# ESP32C3 register map
File version: 1.0
CPU: RISC-V RV32IMC single-core 1, little endian, no MPU, FPU, 3 interrupt priority bits
Registers are 32-bit, read-write, reset 0x0 unless marked. A register's access mark holds for its fields unless they carry their own. Offsets are from the block's base; lines under a group give offsets from that group; [hi:lo] are bit positions; {n}, {i} and the like mark numbered series; 'fields as' and 'values as' point back to an identical list; <NAME> marks a mode.

## Memory map
0x00000000 GPIO_SD size 0xE0
0x00000000 I2C size 0x440
0x00000000 I2S size 0x2E0
0x00000000 INTERRUPT_CORE0 size 0xCE0
0x00000000 MCPWM
0x00000000 SPI size 0x4A0
0x00000000 SPI_MEM size 0x5E0
0x00000000 TIMG size 0x340
0x00000000 UHCI size 0x420
0x60000000 UART size 0x420
0x60002000 SPI1
0x60003000 SPI0
0x60004000 GPIO size 0x18E0
0x60005000 FE2
0x60006000 FE
0x60008000 RTCCNTL size 0x960
0x60008800 EFUSE size 0xE60
0x60009000 IO_MUX
0x6000E000 RTC_I2C size 0x3E0
0x60010000 UART1
0x60013000 I2C_EXT
0x60014000 UHCI0
0x60016000 RMT size 0x340
0x60019000 LEDC size 0x580
0x6001CC00 NRX
0x6001D000 BB
0x6001F000 TIMERGROUP0
0x60020000 TIMERGROUP1
0x60023000 SYS_TIMER size 0x3C0
0x60024000 SPI2
0x60026000 APB_CTRL size 0x500
0x60026000 SYSCON size 0x500
0x6002B000 TWAI
0x6002D000 I2S0
0x6003A000 AES
0x6003B000 SHA
0x6003C000 RSA
0x6003D000 DIGITAL_SIGNATURE
0x6003E000 HMAC
0x6003F000 GDMA size 0xBA0
0x60040000 APB_SARADC size 0x340
0x600C0000 SYSTEM size 0x500
0x600C1000 SENSITIVE size 0xBC0
0x600C2000 INTERRUPT
0x600C3000 DMA_COPY
0x600C4000 EXTMEM size 0x840
0x600CC000 AES_XTS
0x600CE000 ASSIST_DEBUG size 0x500
0x600CF000 DEDICATED_GPIO
0x600D0000 WORLD_CNTL

## APB_CTRL
Base 0x60026000
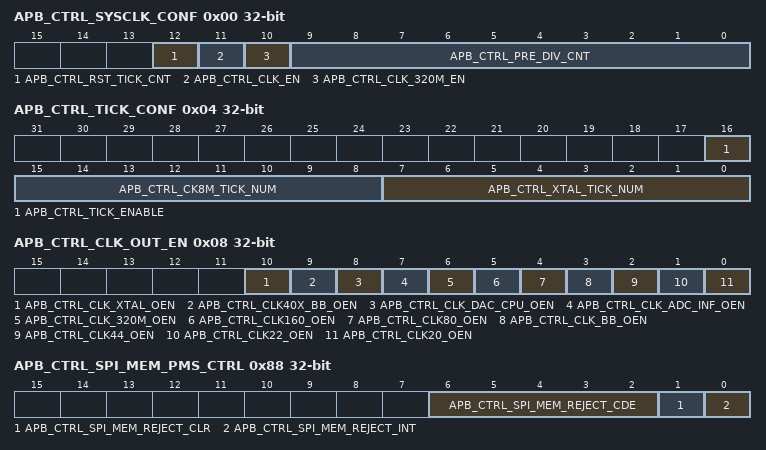
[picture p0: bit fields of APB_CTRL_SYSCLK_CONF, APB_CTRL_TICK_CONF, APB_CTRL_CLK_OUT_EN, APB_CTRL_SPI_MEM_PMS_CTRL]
0x00 APB_CTRL_SYSCLK_CONF
  [12] APB_CTRL_RST_TICK_CNT, [11] APB_CTRL_CLK_EN, [10] APB_CTRL_CLK_320M_EN, [9:0] APB_CTRL_PRE_DIV_CNT
0x04 APB_CTRL_TICK_CONF
  [16] APB_CTRL_TICK_ENABLE, [15:8] APB_CTRL_CK8M_TICK_NUM, [7:0] APB_CTRL_XTAL_TICK_NUM
0x08 APB_CTRL_CLK_OUT_EN
  [10] APB_CTRL_CLK_XTAL_OEN, [9] APB_CTRL_CLK40X_BB_OEN, [8] APB_CTRL_CLK_DAC_CPU_OEN, [7] APB_CTRL_CLK_ADC_INF_OEN, [6] APB_CTRL_CLK_320M_OEN, [5] APB_CTRL_CLK160_OEN, [4] APB_CTRL_CLK80_OEN, [3] APB_CTRL_CLK_BB_OEN, [2] APB_CTRL_CLK44_OEN, [1] APB_CTRL_CLK22_OEN, [0] APB_CTRL_CLK20_OEN
0x0C APB_CTRL_WIFI_BB_CFG
0x10 APB_CTRL_WIFI_BB_CFG_2
0x14 APB_CTRL_WIFI_CLK_EN
0x18 APB_CTRL_WIFI_RST_EN
  [31:0] APB_CTRL_WIFI_RST
0x1C APB_CTRL_HOST_INF_SEL
  [7:0] APB_CTRL_PERI_IO_SWAP
0x20 APB_CTRL_EXT_MEM_PMS_LOCK
  [0] APB_CTRL_EXT_MEM_PMS_LOCK
{0x28+4i} APB_CTRL_FLASH_ACE{i}_ATTR (i=0..3)
  [1:0] APB_CTRL_FLASH_ACE{i}_ATTR
{0x38+4i} APB_CTRL_FLASH_ACE{i}_ADDR (i=0..3)
  [31:0] APB_CTRL_FLASH_ACE{i}_ADDR_S
{0x48+4i} APB_CTRL_FLASH_ACE{i}_SIZE (i=0..3)
  [12:0] APB_CTRL_FLASH_ACE{i}_SIZE
0x88 APB_CTRL_SPI_MEM_PMS_CTRL access per field
  [6:2] APB_CTRL_SPI_MEM_REJECT_CDE ro, [1] APB_CTRL_SPI_MEM_REJECT_CLR wo, [0] APB_CTRL_SPI_MEM_REJECT_INT ro
0x8C APB_CTRL_SPI_MEM_REJECT_ADDR ro
0x90 APB_CTRL_SDIO_CTRL
  [0] APB_CTRL_SDIO_WIN_ACCESS_EN
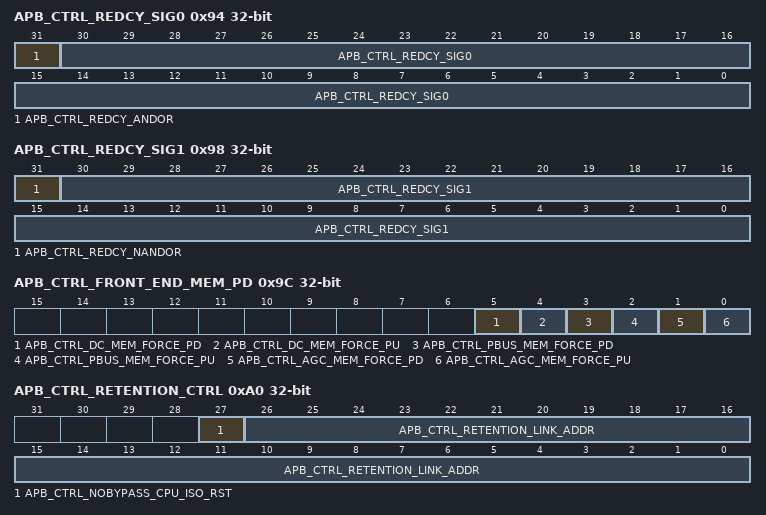
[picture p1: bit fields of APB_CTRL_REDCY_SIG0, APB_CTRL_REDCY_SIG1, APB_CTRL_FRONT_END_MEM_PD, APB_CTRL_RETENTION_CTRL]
0x94 APB_CTRL_REDCY_SIG0 access per field
  [31] APB_CTRL_REDCY_ANDOR ro, [30:0] APB_CTRL_REDCY_SIG0 rw
0x98 APB_CTRL_REDCY_SIG1 access per field
  [31] APB_CTRL_REDCY_NANDOR ro, [30:0] APB_CTRL_REDCY_SIG1 rw
0x9C APB_CTRL_FRONT_END_MEM_PD
  [5] APB_CTRL_DC_MEM_FORCE_PD, [4] APB_CTRL_DC_MEM_FORCE_PU, [3] APB_CTRL_PBUS_MEM_FORCE_PD, [2] APB_CTRL_PBUS_MEM_FORCE_PU, [1] APB_CTRL_AGC_MEM_FORCE_PD, [0] APB_CTRL_AGC_MEM_FORCE_PU
0xA0 APB_CTRL_RETENTION_CTRL
  [27] APB_CTRL_NOBYPASS_CPU_ISO_RST, [26:0] APB_CTRL_RETENTION_LINK_ADDR
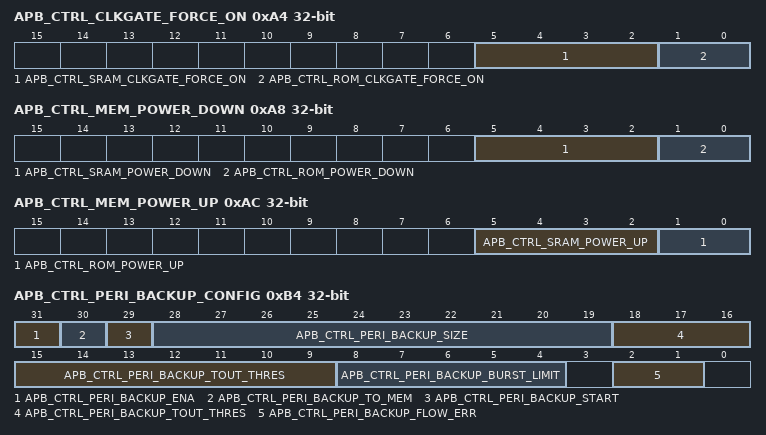
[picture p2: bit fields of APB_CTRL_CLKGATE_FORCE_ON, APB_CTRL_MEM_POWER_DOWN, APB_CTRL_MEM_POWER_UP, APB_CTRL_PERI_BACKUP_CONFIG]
0xA4 APB_CTRL_CLKGATE_FORCE_ON
  [5:2] APB_CTRL_SRAM_CLKGATE_FORCE_ON, [1:0] APB_CTRL_ROM_CLKGATE_FORCE_ON
0xA8 APB_CTRL_MEM_POWER_DOWN
  [5:2] APB_CTRL_SRAM_POWER_DOWN, [1:0] APB_CTRL_ROM_POWER_DOWN
0xAC APB_CTRL_MEM_POWER_UP
  [5:2] APB_CTRL_SRAM_POWER_UP, [1:0] APB_CTRL_ROM_POWER_UP
0xB0 APB_CTRL_RND_DATA ro
0xB4 APB_CTRL_PERI_BACKUP_CONFIG access per field
  [31] APB_CTRL_PERI_BACKUP_ENA rw, [30] APB_CTRL_PERI_BACKUP_TO_MEM rw, [29] APB_CTRL_PERI_BACKUP_START wo, [28:19] APB_CTRL_PERI_BACKUP_SIZE rw, [18:9] APB_CTRL_PERI_BACKUP_TOUT_THRES rw, [8:4] APB_CTRL_PERI_BACKUP_BURST_LIMIT rw, [2:1] APB_CTRL_PERI_BACKUP_FLOW_ERR ro
0xB8 APB_CTRL_PERI_BACKUP_APB_ADDR
  [31:0] APB_CTRL_BACKUP_APB_START_ADDR
0xBC APB_CTRL_PERI_BACKUP_MEM_ADDR
  [31:0] APB_CTRL_BACKUP_MEM_START_ADDR
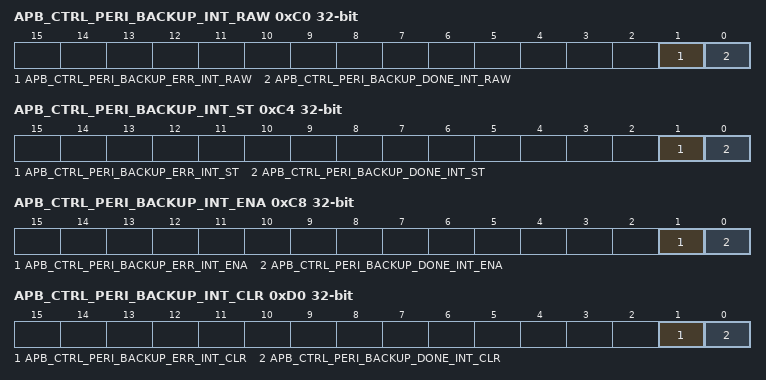
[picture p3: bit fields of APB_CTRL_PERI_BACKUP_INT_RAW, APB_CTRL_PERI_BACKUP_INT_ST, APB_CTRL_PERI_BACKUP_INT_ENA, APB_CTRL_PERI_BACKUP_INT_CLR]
0xC0 APB_CTRL_PERI_BACKUP_INT_RAW ro
  [1] APB_CTRL_PERI_BACKUP_ERR_INT_RAW, [0] APB_CTRL_PERI_BACKUP_DONE_INT_RAW
0xC4 APB_CTRL_PERI_BACKUP_INT_ST ro
  [1] APB_CTRL_PERI_BACKUP_ERR_INT_ST, [0] APB_CTRL_PERI_BACKUP_DONE_INT_ST
0xC8 APB_CTRL_PERI_BACKUP_INT_ENA
  [1] APB_CTRL_PERI_BACKUP_ERR_INT_ENA, [0] APB_CTRL_PERI_BACKUP_DONE_INT_ENA
0xD0 APB_CTRL_PERI_BACKUP_INT_CLR wo
  [1] APB_CTRL_PERI_BACKUP_ERR_INT_CLR, [0] APB_CTRL_PERI_BACKUP_DONE_INT_CLR
0x3FC APB_CTRL_DATE

## SYSCON
Base 0x60026000
Registers as APB_CTRL (with APB_CTRL read as SYSCON).
